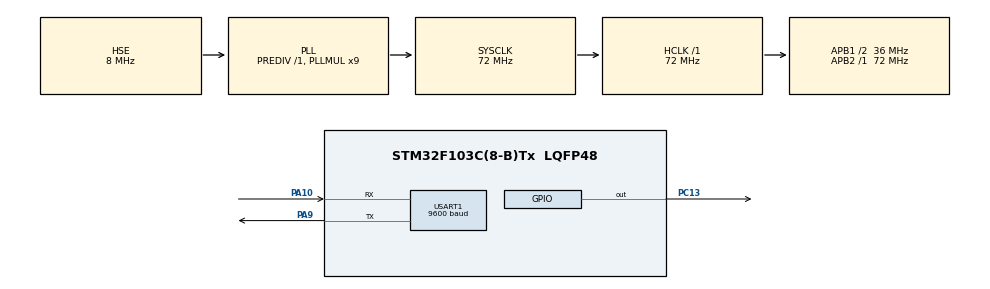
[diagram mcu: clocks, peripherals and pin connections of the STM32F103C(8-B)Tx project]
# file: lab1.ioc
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Mcu.Family=STM32F1
Mcu.Name=STM32F103C(8-B)Tx
Mcu.Package=LQFP48
NVIC.PriorityGroup=NVIC_PRIORITYGROUP_4
NVIC.USART1_IRQn=true\:0\:0\:false\:false\:true\:true\:true
PA10.Mode=Asynchronous
PA10.Signal=USART1_RX
PA13.Mode=Serial_Wire
PA13.Signal=SYS_JTMS-SWDIO
PA14.Mode=Serial_Wire
PA14.Signal=SYS_JTCK-SWCLK
PA9.Mode=Asynchronous
PA9.Signal=USART1_TX
PC13-TAMPER-RTC.Signal=GPIO_Output
PD0-OSC_IN.Mode=HSE-External-Oscillator
PD0-OSC_IN.Signal=RCC_OSC_IN
PD1-OSC_OUT.Mode=HSE-External-Oscillator
PD1-OSC_OUT.Signal=RCC_OSC_OUT
ProjectManager.HeapSize=0x200
ProjectManager.StackSize=0x400
ProjectManager.TargetToolchain=MDK-ARM V5.32
RCC.AHBFreq_Value=72000000
RCC.APB1CLKDivider=RCC_HCLK_DIV2
RCC.APB1Freq_Value=36000000
RCC.APB1TimFreq_Value=72000000
RCC.APB2Freq_Value=72000000
RCC.APB2TimFreq_Value=72000000
RCC.HCLKFreq_Value=72000000
RCC.PLLMUL=RCC_PLL_MUL9
RCC.PLLSourceVirtual=RCC_PLLSOURCE_HSE
RCC.SYSCLKFreq_VALUE=72000000
RCC.SYSCLKSource=RCC_SYSCLKSOURCE_PLLCLK
RCC.USBFreq_Value=72000000
USART1.BaudRate=9600
USART1.VirtualMode=VM_ASYNC
board=custom

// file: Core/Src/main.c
/* USER CODE BEGIN Header */
/**
  ******************************************************************************
  * @file           : main.c
  * @brief          : Main program body
  ******************************************************************************
  * @attention
  *
  * <h2><center>&copy; Copyright (c) 2022 STMicroelectronics.
  * All rights reserved.</center></h2>
  *
  * This software component is licensed by ST under BSD 3-Clause license,
  * the "License"; You may not use this file except in compliance with the
  * License. You may obtain a copy of the License at:
  *                        opensource.org/licenses/BSD-3-Clause
  *
  ******************************************************************************
  */
/* USER CODE END Header */
#include "main.h"

/* USER CODE BEGIN Includes */
#include <stdio.h>
#include <string.h>
#include <stdbool.h>
/* USER CODE END Includes */

/* USER CODE BEGIN PD */
#define MAX_LEN 18
/* USER CODE END PD */

UART_HandleTypeDef huart1;

/* USER CODE BEGIN PV */
uint8_t *subString(uint8_t *s, int pos, int index);
bool StrCompare (uint8_t *pBuff, uint8_t *Sample, uint8_t nSize);
bool WriteCom(uint8_t *pBuff, uint8_t nSize);
bool ReadComm(uint8_t *pBuff, uint8_t nSize);
bool serialProcess(void);

/* USER CODE END PV */

void SystemClock_Config(void);
static void MX_GPIO_Init(void);
static void MX_USART1_UART_Init(void);

/* USER CODE BEGIN 0 */
uint8_t nRxData[MAX_LEN];
uint8_t nTxData[MAX_LEN];
uint8_t strCommand[4];
uint8_t strOpt[3];
uint8_t strData[8];

bool bDataAvailable = false;
uint8_t STX[]= {0x02U};
uint8_t ETX[]= {0x03U};
uint8_t ACK[]= {0x06U};
uint8_t SYN[]= {0x16U};

uint8_t led_control;
/* USER CODE END 0 */

int main(void)
{

  /* MCU Configuration--------------------------------------------------------*/

  /* Reset of all peripherals, Initializes the Flash interface and the Systick. */
  HAL_Init();

  /* Configure the system clock */
  SystemClock_Config();

  /* Initialize all configured peripherals */
  MX_GPIO_Init();
  MX_USART1_UART_Init();
  /* USER CODE BEGIN 2 */
  HAL_UART_Receive_IT(&huart1, (uint8_t *)nRxData, MAX_LEN);
  /* USER CODE END 2 */

  /* Infinite loop */
  while (1)
  {

    /* USER CODE BEGIN 3 */
    serialProcess();
  }
  /* USER CODE END 3 */
}

void SystemClock_Config(void)
{
  RCC_OscInitTypeDef RCC_OscInitStruct = {0};
  RCC_ClkInitTypeDef RCC_ClkInitStruct = {0};

  /** Initializes the RCC Oscillators according to the specified parameters
  * in the RCC_OscInitTypeDef structure.
  */
  RCC_OscInitStruct.OscillatorType = RCC_OSCILLATORTYPE_HSE;
  RCC_OscInitStruct.HSEState = RCC_HSE_ON;
  RCC_OscInitStruct.HSEPredivValue = RCC_HSE_PREDIV_DIV1;
  RCC_OscInitStruct.HSIState = RCC_HSI_ON;
  RCC_OscInitStruct.PLL.PLLState = RCC_PLL_ON;
  RCC_OscInitStruct.PLL.PLLSource = RCC_PLLSOURCE_HSE;
  RCC_OscInitStruct.PLL.PLLMUL = RCC_PLL_MUL9;
  if (HAL_RCC_OscConfig(&RCC_OscInitStruct) != HAL_OK)
  {
    Error_Handler();
  }
  /** Initializes the CPU, AHB and APB buses clocks
  */
  RCC_ClkInitStruct.ClockType = RCC_CLOCKTYPE_HCLK|RCC_CLOCKTYPE_SYSCLK
                              |RCC_CLOCKTYPE_PCLK1|RCC_CLOCKTYPE_PCLK2;
  RCC_ClkInitStruct.SYSCLKSource = RCC_SYSCLKSOURCE_PLLCLK;
  RCC_ClkInitStruct.AHBCLKDivider = RCC_SYSCLK_DIV1;
  RCC_ClkInitStruct.APB1CLKDivider = RCC_HCLK_DIV2;
  RCC_ClkInitStruct.APB2CLKDivider = RCC_HCLK_DIV1;

  if (HAL_RCC_ClockConfig(&RCC_ClkInitStruct, FLASH_LATENCY_2) != HAL_OK)
  {
    Error_Handler();
  }
}

static void MX_USART1_UART_Init(void)
{

  huart1.Instance = USART1;
  huart1.Init.BaudRate =115200 ;
  huart1.Init.WordLength = UART_WORDLENGTH_8B;
  huart1.Init.StopBits = UART_STOPBITS_1;
  huart1.Init.Parity = UART_PARITY_NONE;
  huart1.Init.Mode = UART_MODE_TX_RX;
  huart1.Init.HwFlowCtl = UART_HWCONTROL_NONE;
  huart1.Init.OverSampling = UART_OVERSAMPLING_16;
  if (HAL_UART_Init(&huart1) != HAL_OK)
  {
    Error_Handler();
  }

}

static void MX_GPIO_Init(void)
{
  GPIO_InitTypeDef GPIO_InitStruct = {0};

  /* GPIO Ports Clock Enable */
  __HAL_RCC_GPIOC_CLK_ENABLE();
  __HAL_RCC_GPIOD_CLK_ENABLE();
  __HAL_RCC_GPIOA_CLK_ENABLE();

  /*Configure GPIO pin Output Level */
  HAL_GPIO_WritePin(GPIOC, GPIO_PIN_13, GPIO_PIN_RESET);

  /*Configure GPIO pin : PC13 */
  GPIO_InitStruct.Pin = GPIO_PIN_13;
  GPIO_InitStruct.Mode = GPIO_MODE_OUTPUT_PP;
  GPIO_InitStruct.Pull = GPIO_NOPULL;
  GPIO_InitStruct.Speed = GPIO_SPEED_FREQ_LOW;
  HAL_GPIO_Init(GPIOC, &GPIO_InitStruct);

}

/* USER CODE BEGIN 4 */
uint8_t *subString(uint8_t *s, int pos, int index)
{
  uint8_t *t = &s[pos];
  s[pos - 1] = '\0';
  for (int i = index; i<(strlen((char*)t)+1); i++)
  {
    t[i] = '\0';
  }
  return t;
}

bool StrCompare (uint8_t *pBuff, uint8_t *Sample, uint8_t nSize)
{
  for (int i =0 ; i <nSize; i++)
  {
    if(pBuff[i] != Sample[i])
    {
      return false;
    }
  }

  return true;
}

bool WriteCom(uint8_t *pBuff, uint8_t nSize)
{
  return HAL_UART_Transmit(&huart1, pBuff, nSize, 1000);
}

bool ReadComm(uint8_t *pBuff, uint8_t nSize)
{
  if((pBuff[0] == STX[0] && (pBuff[17] == ETX[0])))
  {
    memcpy(strCommand, subString(pBuff, 1,4), 4);
    memcpy(strOpt, subString(pBuff, 5,3), 3);
    memcpy(strData, subString(pBuff, 8,8), 8);

    bDataAvailable = true;
  }
  else
  {
    bDataAvailable = false;
  }
  return bDataAvailable;
}

void HAL_UART_RxCpltCallback(UART_HandleTypeDef *huart)
{
  if(huart ->Instance == huart1.Instance)
  {
    ReadComm(nRxData, MAX_LEN);
    HAL_UART_Receive_IT(&huart1, (uint8_t*)nRxData, MAX_LEN);
  }
}

bool serialProcess(void)
{
  uint8_t nIndex = 0;

  if(bDataAvailable == true)
  {
  if(StrCompare(strCommand, (uint8_t *)"MOVL", 4))
  {
    memcpy(nTxData + nIndex, STX, 1);
    nIndex += 1;
    memcpy(nTxData + nIndex, strCommand, 4);
    nIndex+=4;
    memcpy(nTxData + nIndex, strOpt, 3);
    nIndex += 3;
    memcpy(nTxData + nIndex, strData, 8);
    nIndex+=8;
    memcpy(nTxData + nIndex, ACK, 1);
    nIndex += 1;
    memcpy(nTxData + nIndex, ETX, 1);

    WriteCom(nTxData, MAX_LEN);
  }

  else if(StrCompare(strCommand, (uint8_t *)"GPOS", 4))
  {
        memcpy(nTxData + nIndex, STX, 1);
    nIndex += 1;
    memcpy(nTxData + nIndex, strCommand, 4);
    nIndex+=4;
    memcpy(nTxData + nIndex, strOpt, 3);
    nIndex += 3;
    memcpy(nTxData + nIndex, strData, 8);
    nIndex+=8;
    memcpy(nTxData + nIndex, ACK, 1);
    nIndex += 1;
    memcpy(nTxData + nIndex, ETX, 1);

    WriteCom(nTxData, MAX_LEN);
  }

  else if(StrCompare(strCommand, (uint8_t *)"GVEL", 4))
  {
    memcpy(nTxData + nIndex, STX, 1);
    nIndex += 1;
    memcpy(nTxData + nIndex, (uint8_t *) strCommand, 4);
    nIndex+=4;
    memcpy(nTxData + nIndex, (uint8_t *) strOpt, 3);
    nIndex += 3;
    memcpy(nTxData + nIndex, (uint8_t *) strData, 8);
    nIndex+=8;
    memcpy(nTxData + nIndex, ACK, 1);
    nIndex += 1;
    memcpy(nTxData + nIndex, ETX, 1);
    nIndex += 1;

    WriteCom(nTxData, MAX_LEN);
  }

    else if(StrCompare(strCommand, (uint8_t *)"GSTT", 4))
  {
    memcpy(nTxData + nIndex, STX, 1);
    nIndex += 1;
    memcpy(nTxData + nIndex, (uint8_t *) strCommand, 4);
    nIndex+=4;
    memcpy(nTxData + nIndex, (uint8_t *) strOpt, 3);
    nIndex += 3;
    memcpy(nTxData + nIndex, (uint8_t *) strData, 8);
    nIndex+=8;
    memcpy(nTxData + nIndex, (uint8_t *) ACK, 1);
    nIndex += 1;
    memcpy(nTxData + nIndex, ETX, 1);
    nIndex += 1;

    WriteCom(nTxData, MAX_LEN);
  }

	else if(StrCompare(strCommand, (uint8_t *)"RESS", 4))
  {
	 led_control = 1;
    memcpy(nTxData + nIndex, STX, 1);
    nIndex += 1;
    memcpy(nTxData + nIndex, (uint8_t *) strCommand, 4);
    nIndex+=4;
    memcpy(nTxData + nIndex, (uint8_t *) strOpt, 3);
    nIndex += 3;
    memcpy(nTxData + nIndex, (uint8_t *) strData, 8);
    nIndex+=8;
    memcpy(nTxData + nIndex, (uint8_t *) ACK, 1);
    nIndex += 1;
    memcpy(nTxData + nIndex, ETX, 1);
    nIndex += 1;

    WriteCom(nTxData, MAX_LEN);
  }

  else if(StrCompare(strCommand, (uint8_t *)"SETT", 4))
  {
	led_control = 2;
    memcpy(nTxData + nIndex, STX, 1);
    nIndex += 1;
    memcpy(nTxData + nIndex, (uint8_t *) strCommand, 4);
    nIndex+=4;
    memcpy(nTxData + nIndex, (uint8_t *) strOpt, 3);
    nIndex += 3;
    memcpy(nTxData + nIndex, (uint8_t *) strData, 8);
    nIndex+=8;
    memcpy(nTxData + nIndex, (uint8_t *) ACK, 1);
    nIndex += 1;
    memcpy(nTxData + nIndex, ETX, 1);
    nIndex += 1;

    WriteCom(nTxData, MAX_LEN);
  }

  else if(StrCompare(strCommand, (uint8_t *)"TOGG", 4))
  {
	led_control =3;
    memcpy(nTxData + nIndex, STX, 1);
    nIndex += 1;
    memcpy(nTxData + nIndex, (uint8_t *) strCommand, 4);
    nIndex+=4;
    memcpy(nTxData + nIndex, (uint8_t *) strOpt, 3);
    nIndex += 3;
    memcpy(nTxData + nIndex, (uint8_t *) strData, 8);
    nIndex+=8;
    memcpy(nTxData + nIndex, (uint8_t *) ACK, 1);
    nIndex += 1;
    memcpy(nTxData + nIndex, ETX, 1);
    nIndex += 1;

    WriteCom(nTxData, MAX_LEN);
  }

    else
  {
    memcpy(nTxData + nIndex, STX, 1);
    nIndex += 1;
    memcpy(nTxData + nIndex, (uint8_t *) "NULL", 4);
    nIndex+=4;
    memcpy(nTxData + nIndex, (uint8_t *) strOpt, 3);
    nIndex += 3;
    memcpy(nTxData + nIndex, (uint8_t *) strData, 8);
    nIndex+=8;
    memcpy(nTxData + nIndex, ACK, 1);
    nIndex += 1;
    memcpy(nTxData + nIndex, ETX, 1);
    nIndex += 1;

    WriteCom(nTxData, MAX_LEN);
  }

  bDataAvailable = false;
}

	if(led_control == 1)
		{
		HAL_GPIO_WritePin(GPIOC, GPIO_PIN_13, GPIO_PIN_SET);
		}

	if(led_control == 2)
		{
		HAL_GPIO_WritePin(GPIOC, GPIO_PIN_13, GPIO_PIN_RESET);
		}
	if(led_control == 3)
		{
		HAL_GPIO_TogglePin(GPIOC, GPIO_PIN_13);
		HAL_Delay(500);
		}
return true;
}
/* USER CODE END 4 */

void Error_Handler(void)
{
  __disable_irq();
  while (1)
  {
  }
}

/************************ (C) COPYRIGHT STMicroelectronics *****END OF FILE****/
